# alb32r003x register map
Vendor: ALB; Series: ALB RT SoC
CPU: ALB XF, little endian
Registers are 32-bit, access not given, reset 0x0 unless marked. A register's access mark holds for its fields unless they carry their own. Offsets are from the block's base; [hi:lo] are bit positions; {n}, {i} and the like mark numbered series.

## CLB1
Base 0x2A000000
Same registers: CLB2 0x2A000800, CLB3 0x2A001000, CLB4 0x2A001800
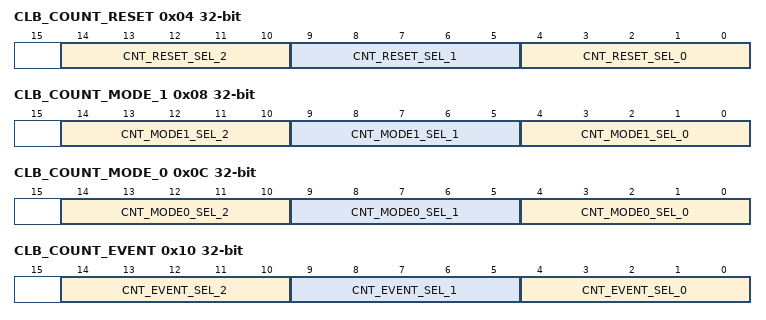
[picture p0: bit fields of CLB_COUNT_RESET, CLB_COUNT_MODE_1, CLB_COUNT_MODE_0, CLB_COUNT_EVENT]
0x04 CLB_COUNT_RESET
  [14:10] CNT_RESET_SEL_2, [9:5] CNT_RESET_SEL_1, [4:0] CNT_RESET_SEL_0
0x08 CLB_COUNT_MODE_1
  [14:10] CNT_MODE1_SEL_2, [9:5] CNT_MODE1_SEL_1, [4:0] CNT_MODE1_SEL_0
0x0C CLB_COUNT_MODE_0
  [14:10] CNT_MODE0_SEL_2, [9:5] CNT_MODE0_SEL_1, [4:0] CNT_MODE0_SEL_0
0x10 CLB_COUNT_EVENT
  [14:10] CNT_EVENT_SEL_2, [9:5] CNT_EVENT_SEL_1, [4:0] CNT_EVENT_SEL_0
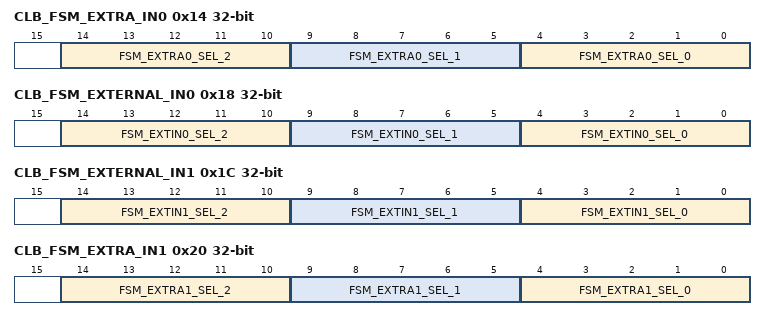
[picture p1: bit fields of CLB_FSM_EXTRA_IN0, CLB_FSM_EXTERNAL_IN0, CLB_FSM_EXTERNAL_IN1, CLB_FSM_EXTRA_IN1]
0x14 CLB_FSM_EXTRA_IN0
  [14:10] FSM_EXTRA0_SEL_2, [9:5] FSM_EXTRA0_SEL_1, [4:0] FSM_EXTRA0_SEL_0
0x18 CLB_FSM_EXTERNAL_IN0
  [14:10] FSM_EXTIN0_SEL_2, [9:5] FSM_EXTIN0_SEL_1, [4:0] FSM_EXTIN0_SEL_0
0x1C CLB_FSM_EXTERNAL_IN1
  [14:10] FSM_EXTIN1_SEL_2, [9:5] FSM_EXTIN1_SEL_1, [4:0] FSM_EXTIN1_SEL_0
0x20 CLB_FSM_EXTRA_IN1
  [14:10] FSM_EXTRA1_SEL_2, [9:5] FSM_EXTRA1_SEL_1, [4:0] FSM_EXTRA1_SEL_0
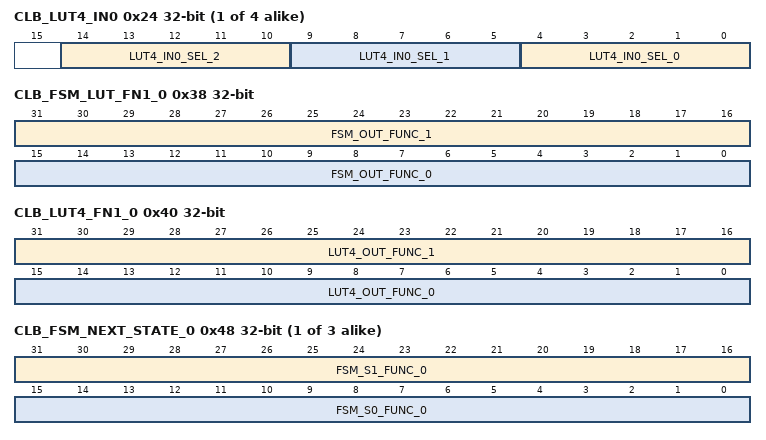
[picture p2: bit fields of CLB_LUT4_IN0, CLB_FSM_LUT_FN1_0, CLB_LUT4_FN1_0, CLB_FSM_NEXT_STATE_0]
{0x24+4i} CLB_LUT4_IN{i} (i=0..3)
  [14:10] LUT4_IN{i}_SEL_2, [9:5] LUT4_IN{i}_SEL_1, [4:0] LUT4_IN{i}_SEL_0
0x38 CLB_FSM_LUT_FN1_0
  [31:16] FSM_OUT_FUNC_1, [15:0] FSM_OUT_FUNC_0
0x3C CLB_FSM_LUT_FN2
  [15:0] FSM_OUT_FUNC_2
0x40 CLB_LUT4_FN1_0
  [31:16] LUT4_OUT_FUNC_1, [15:0] LUT4_OUT_FUNC_0
0x44 CLB_LUT4_FN2
  [15:0] LUT4_OUT_FUNC_2
{0x48+4i} CLB_FSM_NEXT_STATE_{i} (i=0..2)
  [31:16] FSM_S1_FUNC_{i}, [15:0] FSM_S0_FUNC_{i}
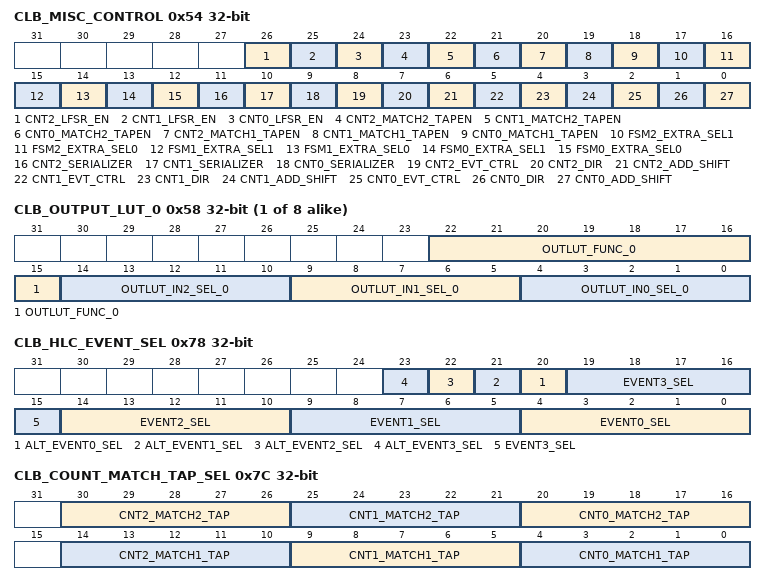
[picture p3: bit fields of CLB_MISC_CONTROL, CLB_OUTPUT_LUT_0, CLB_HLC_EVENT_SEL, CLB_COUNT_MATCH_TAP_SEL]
0x54 CLB_MISC_CONTROL
  [26] CNT2_LFSR_EN, [25] CNT1_LFSR_EN, [24] CNT0_LFSR_EN, [23] CNT2_MATCH2_TAPEN, [22] CNT1_MATCH2_TAPEN, [21] CNT0_MATCH2_TAPEN, [20] CNT2_MATCH1_TAPEN, [19] CNT1_MATCH1_TAPEN, [18] CNT0_MATCH1_TAPEN, [17] FSM2_EXTRA_SEL1, [16] FSM2_EXTRA_SEL0, [15] FSM1_EXTRA_SEL1, [14] FSM1_EXTRA_SEL0, [13] FSM0_EXTRA_SEL1, [12] FSM0_EXTRA_SEL0, [11] CNT2_SERIALIZER, [10] CNT1_SERIALIZER, [9] CNT0_SERIALIZER, [8] CNT2_EVT_CTRL, [7] CNT2_DIR, [6] CNT2_ADD_SHIFT, [5] CNT1_EVT_CTRL, [4] CNT1_DIR, [3] CNT1_ADD_SHIFT, [2] CNT0_EVT_CTRL, [1] CNT0_DIR, [0] CNT0_ADD_SHIFT
{0x58+4i} CLB_OUTPUT_LUT_{i} (i=0..7)
  [22:15] OUTLUT_FUNC_{i}, [14:10] OUTLUT_IN2_SEL_{i}, [9:5] OUTLUT_IN1_SEL_{i}, [4:0] OUTLUT_IN0_SEL_{i}
0x78 CLB_HLC_EVENT_SEL
  [n+20] ALT_EVENT{n}_SEL (n=0..3), [5n+4:5n] EVENT{n}_SEL (n=0..3)
0x7C CLB_COUNT_MATCH_TAP_SEL
  [30:26] CNT2_MATCH2_TAP — LUT Control
  [25:21] CNT1_MATCH2_TAP — LUT Control
  [20:16] CNT0_MATCH2_TAP — LUT Control
  [14:10] CNT2_MATCH1_TAP — LUT Control
  [9:5] CNT1_MATCH1_TAP — LUT Control
  [4:0] CNT0_MATCH1_TAP — LUT Control
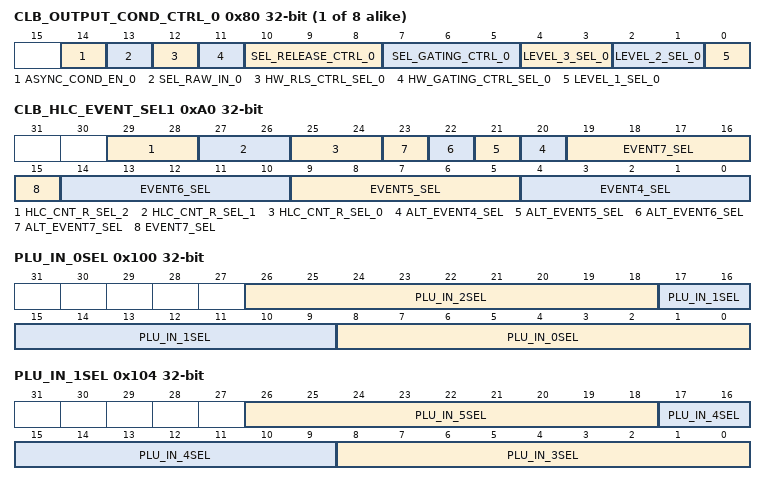
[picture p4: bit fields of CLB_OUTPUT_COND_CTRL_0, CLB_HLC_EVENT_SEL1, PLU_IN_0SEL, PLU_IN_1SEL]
{0x80+4i} CLB_OUTPUT_COND_CTRL_{i} (i=0..7)
  [14] ASYNC_COND_EN_{i}, [13] SEL_RAW_IN_{i}, [12] HW_RLS_CTRL_SEL_{i}, [11] HW_GATING_CTRL_SEL_{i}, [10:8] SEL_RELEASE_CTRL_{i}, [7:5] SEL_GATING_CTRL_{i}, [4:3] LEVEL_3_SEL_{i}, [2:1] LEVEL_2_SEL_{i}, [0] LEVEL_1_SEL_{i}
0xA0 CLB_HLC_EVENT_SEL1
  [29:28] HLC_CNT_R_SEL_2, [27:26] HLC_CNT_R_SEL_1, [25:24] HLC_CNT_R_SEL_0, [n+16] ALT_EVENT{n}_SEL (n=4..7), [5n-16:5n-20] EVENT{n}_SEL (n=4..7)
0x100 PLU_IN_0SEL
  [26:18] PLU_IN_2SEL — plu2输入选择寄存器
  [17:9] PLU_IN_1SEL — plu1输入选择寄存器
  [8:0] PLU_IN_0SEL — plu0输入选择寄存器
0x104 PLU_IN_1SEL
  [26:18] PLU_IN_5SEL — plu5输入选择寄存器
  [17:9] PLU_IN_4SEL — plu4输入选择寄存器
  [8:0] PLU_IN_3SEL — plu3输入选择寄存器
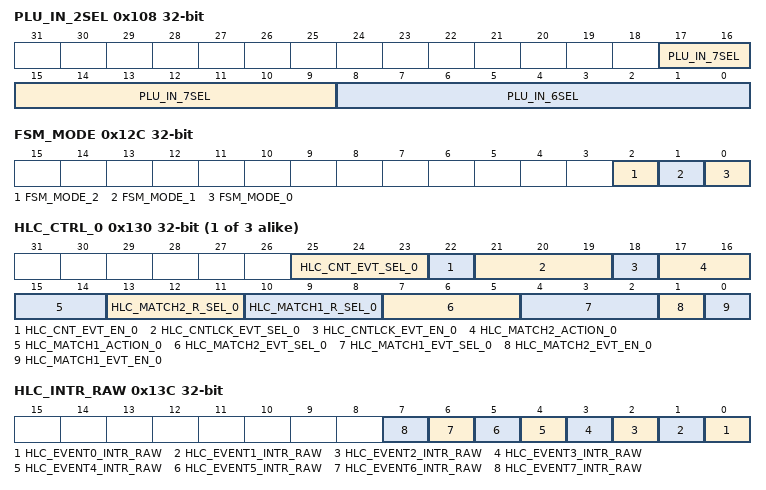
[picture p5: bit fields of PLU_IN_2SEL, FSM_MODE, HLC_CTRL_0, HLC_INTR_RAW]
0x108 PLU_IN_2SEL
  [17:9] PLU_IN_7SEL — plu7输入选择寄存器
  [8:0] PLU_IN_6SEL — plu6输入选择寄存器
0x10C PLU_HALT_EN
  [1:0] PLU_HALT_EN — PLU halt信号使能配置寄存器，只有PLU1使用
{0x110+8i} CNT{i}_MATCH1_REF (i=0..2)
  [31:0] CNT{i}_MATCH1_REF — Reserved
{0x114+8i} CNT{i}_MATCH2_REF (i=0..2)
  [31:0] CNT{i}_MATCH2_REF — Reserved
0x12C FSM_MODE
  [2] FSM_MODE_2, [1] FSM_MODE_1, [0] FSM_MODE_0
{0x130+4i} HLC_CTRL_{i} (i=0..2)
  [25:23] HLC_CNT_EVT_SEL_{i}, [22] HLC_CNT_EVT_EN_{i}, [21:19] HLC_CNTLCK_EVT_SEL_{i}, [18] HLC_CNTLCK_EVT_EN_{i}, [17:16] HLC_MATCH2_ACTION_{i}, [15:14] HLC_MATCH1_ACTION_{i}, [13:11] HLC_MATCH2_R_SEL_{i}, [10:8] HLC_MATCH1_R_SEL_{i}, [7:5] HLC_MATCH2_EVT_SEL_{i}, [4:2] HLC_MATCH1_EVT_SEL_{i}, [1] HLC_MATCH2_EVT_EN_{i}, [0] HLC_MATCH1_EVT_EN_{i}
0x13C HLC_INTR_RAW
  [n] HLC_EVENT{n}_INTR_RAW (n=0..7)
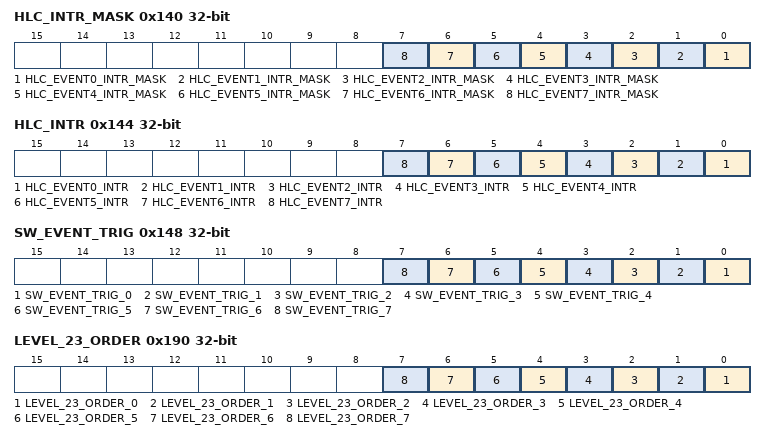
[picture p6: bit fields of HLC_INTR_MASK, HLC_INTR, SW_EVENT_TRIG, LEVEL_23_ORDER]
0x140 HLC_INTR_MASK
  [n] HLC_EVENT{n}_INTR_MASK (n=0..7)
0x144 HLC_INTR
  [n] HLC_EVENT{n}_INTR (n=0..7)
0x148 SW_EVENT_TRIG
  [n] SW_EVENT_TRIG_{n} (n=0..7)
{0x150+8i} RISING_DELAY_{i} (i=0..7)
  [23:0] RISING_DELAY_{i}
{0x154+8i} FALLING_DELAY_{i} (i=0..7)
  [23:0] FALLING_DELAY_{i}
0x190 LEVEL_23_ORDER
  [n] LEVEL_23_ORDER_{n} (n=0..7)
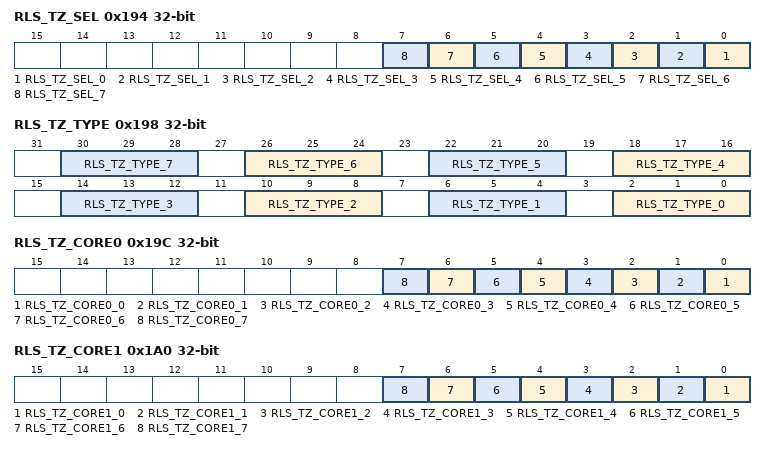
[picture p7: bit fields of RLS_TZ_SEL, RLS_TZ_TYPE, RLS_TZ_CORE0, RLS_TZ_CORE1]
0x194 RLS_TZ_SEL
  [n] RLS_TZ_SEL_{n} (n=0..7)
0x198 RLS_TZ_TYPE
  [4n+2:4n] RLS_TZ_TYPE_{n} (n=0..7)
0x19C RLS_TZ_CORE0
  [n] RLS_TZ_CORE0_{n} (n=0..7)
0x1A0 RLS_TZ_CORE1
  [n] RLS_TZ_CORE1_{n} (n=0..7)
{0x1A4+4i} LOAD_VALUE_{i} (i=0..2)
  [31:0] LOAD_VALUE_{i} — Reserved
0x1FC PLU_REGS_LOCK
  [31:0] PLU_REGS_LOCK — 锁定寄存器。对该寄存器写入lock值后，对受lock保护的所有寄存器不能写入。写其余值无影响；
0x200 CLB_LOAD_EN 16-bit
  [1] GLOBAL_EN
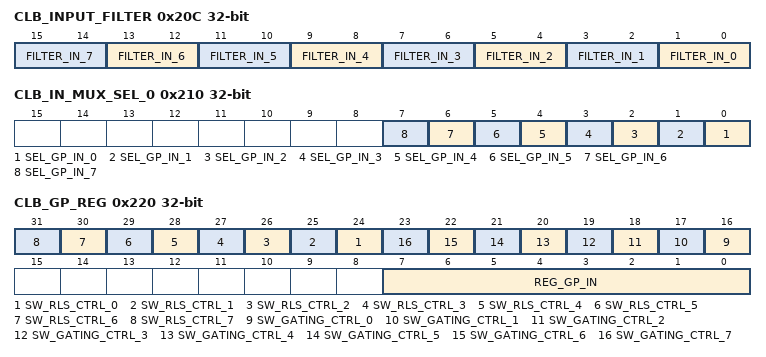
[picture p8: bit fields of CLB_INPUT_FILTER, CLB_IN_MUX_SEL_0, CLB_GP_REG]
0x20C CLB_INPUT_FILTER
  [2n+1:2n] FILTER_IN_{n} (n=0..7)
0x210 CLB_IN_MUX_SEL_0
  [n] SEL_GP_IN_{n} (n=0..7)
0x220 CLB_GP_REG
  [n+24] SW_RLS_CTRL_{n} (n=0..7), [n+16] SW_GATING_CTRL_{n} (n=0..7), [7:0] REG_GP_IN
{0x260+4i} CLB_DBG_R{i} (i=0..3)
  [31:0] HLC_R{i} — Reserved
{0x270+4i} CLB_DBG_C{i} (i=0..2)
  [31:0] COUNTER{i}_OUT — Reserved
0x27C CLB_DBG_OUT
  [31:0] PLU_DBG_OUT — Reserved
{0x270+4i} CLB_DBG_R{i} (i=4..7)
  [31:0] HLC_R{i} — Reserved
0x290 PLU_DBG_IN
  [31:0] PLU_DBG_IN — Reserved
{0x294+4i} COUNTER{i}_LOCK_RPT (i=0..2)
  [31:0] COUNTER{i}_LOCK_RPT — Reserved
